# TC37X register map
File version: 1.0.0
CPU: CM4 r0p1, little endian, MPU, FPU, VTOR, 3 interrupt priority bits
Registers are 16-bit, read-write, reset 0x0 unless marked. A register's access mark holds for its fields unless they carry their own. Offsets are from the block's base; [hi:lo] are bit positions; {n}, {i} and the like mark numbered series; 'fields as' and 'values as' point back to an identical list.

## DMA — ce_sadma
Base 0xF0010000
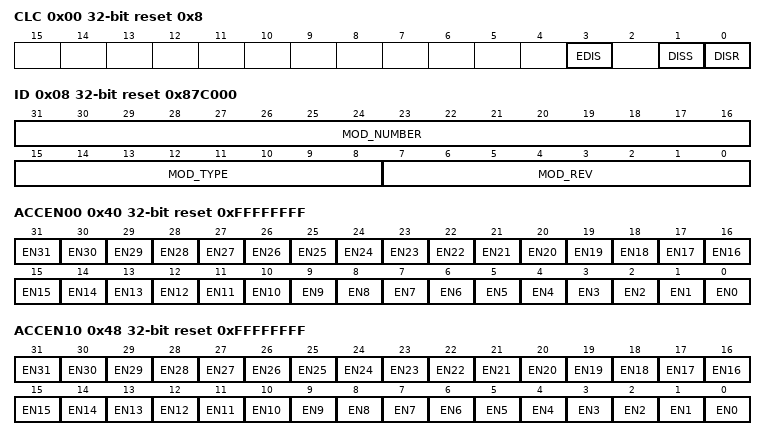
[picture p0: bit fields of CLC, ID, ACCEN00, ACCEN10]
0x00 CLC 32-bit reset 0x8 — DMA Clock Control Register
  [3] EDIS — Sleep Mode Enable Control - EDIS
  [1] DISS ro — Module Disable Status Bit - DISS
  [0] DISR — Module Disable Request Bit - DISR
0x08 ID 32-bit ro reset 0x87C000 (reset mask 0xFFFFFF00) — DMA Identification Register
  [31:16] MOD_NUMBER — Module Number Value - MOD_NUMBER
  [15:8] MOD_TYPE — Module Type - MOD_TYPE
  [7:0] MOD_REV — Module Revision Number - MOD_REV
0x40 ACCEN00 32-bit reset 0xFFFFFFFF — RP 0 Access Enable Register 0
  [n] EN{n} (n=0..31) — Access Enable for Master TAG ID q - ENq
0x44 ACCEN01 32-bit ro — RP 0 Access Enable Register 1
0x48 ACCEN10 32-bit reset 0xFFFFFFFF — RP 1 Access Enable Register 0
  [n] EN{n} (n=0..31) — Access Enable for Master TAG ID q - ENq
0x4C ACCEN11 32-bit ro — RP 1 Access Enable Register 1
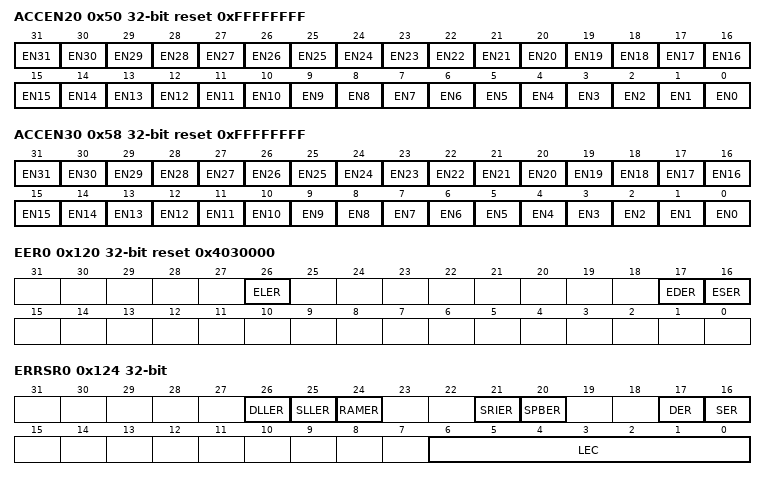
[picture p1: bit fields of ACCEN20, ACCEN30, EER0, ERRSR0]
0x50 ACCEN20 32-bit reset 0xFFFFFFFF — RP 2 Access Enable Register 0
  [n] EN{n} (n=0..31) — Access Enable for Master TAG ID q - ENq
0x54 ACCEN21 32-bit ro — RP 2 Access Enable Register 1
0x58 ACCEN30 32-bit reset 0xFFFFFFFF — RP 3 Access Enable Register 0
  [n] EN{n} (n=0..31) — Access Enable for Master TAG ID q - ENq
0x5C ACCEN31 32-bit ro — RP 3 Access Enable Register 1
0x120 EER0 32-bit reset 0x4030000 — ME 0 Enable Error Register
  [26] ELER — Enable ME DMA Linked List Error - ELER
  [17] EDER — Enable ME Destination Error - EDER
  [16] ESER — Enable ME Source Error - ESER
0x124 ERRSR0 32-bit ro — ME 0 Error Status Register
  [26] DLLER — ME DMA Linked List Error - DLLER
  [25] SLLER — ME Safe Linked List Error - SLLER
  [24] RAMER — ME RAM Error - RAMER
  [21] SRIER — ME SRI Bus Error - SRIER
  [20] SPBER — ME SPB Bus Error - SPBER
  [17] DER — ME Destination Error - DER
  [16] SER — ME Source Error - SER
  [6:0] LEC — ME Last Error Channel - LEC
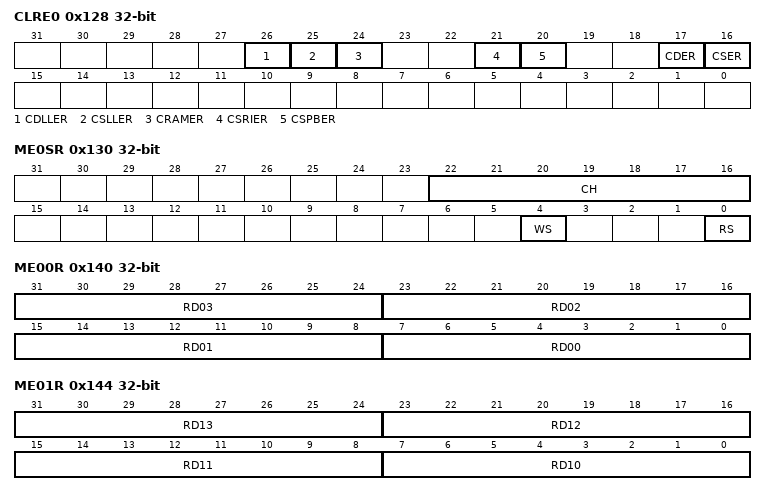
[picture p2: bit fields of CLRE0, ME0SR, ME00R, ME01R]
0x128 CLRE0 32-bit — ME 0 Clear Error Register
  [26] CDLLER wo — Clear DLL Error - CDLLER
  [25] CSLLER wo — Clear SLL Error - CSLLER
  [24] CRAMER wo — Clear RAM Error - CRAMER
  [21] CSRIER wo — Clear SRI Error - CSRIER
  [20] CSPBER wo — Clear SPB Error - CSPBER
  [17] CDER wo — Clear ME Destination Error - CDER
  [16] CSER wo — Clear ME Source Error - CSER
0x130 ME0SR 32-bit ro — ME 0 Status Register
  [22:16] CH — ME Active Channel - CH
  [4] WS — ME Write Status - WS
  [0] RS — ME Read Status - RS
0x140 ME00R 32-bit ro — ME 0 Read Register 0
  [8n+7:8n] RD{n:02} (n=0..3) — DMA Read Move Data Byte - RD{n:02}
0x144 ME01R 32-bit ro — ME 0 Read Register 1
  [8n-73:8n-80] RD{n} (n=10..13) — DMA Read Move Data Byte - RD{n}
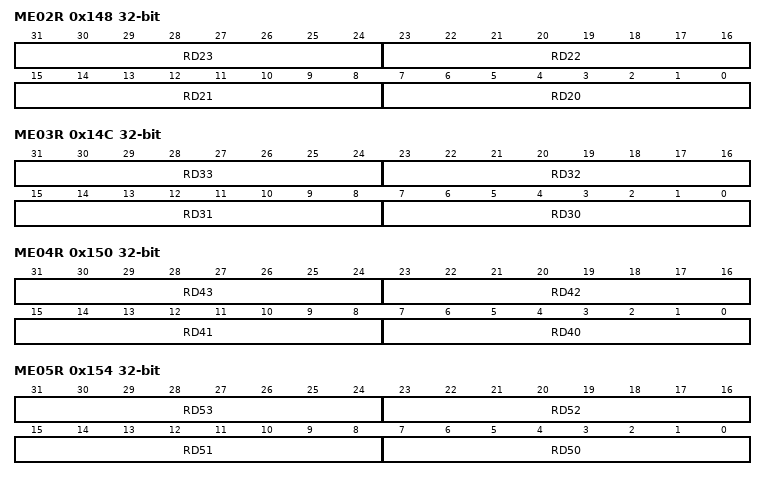
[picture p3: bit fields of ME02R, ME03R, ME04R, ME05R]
0x148 ME02R 32-bit ro — ME 0 Read Register 2
  [8n-153:8n-160] RD{n} (n=20..23) — DMA Read Move Data Byte - RD{n}
0x14C ME03R 32-bit ro — ME 0 Read Register 3
  [8n-233:8n-240] RD{n} (n=30..33) — DMA Read Move Data Byte - RD{n}
0x150 ME04R 32-bit ro — ME 0 Read Register 4
  [8n-313:8n-320] RD{n} (n=40..43) — DMA Read Move Data Byte - RD{n}
0x154 ME05R 32-bit ro — ME 0 Read Register 5
  [8n-393:8n-400] RD{n} (n=50..53) — DMA Read Move Data Byte - RD{n}
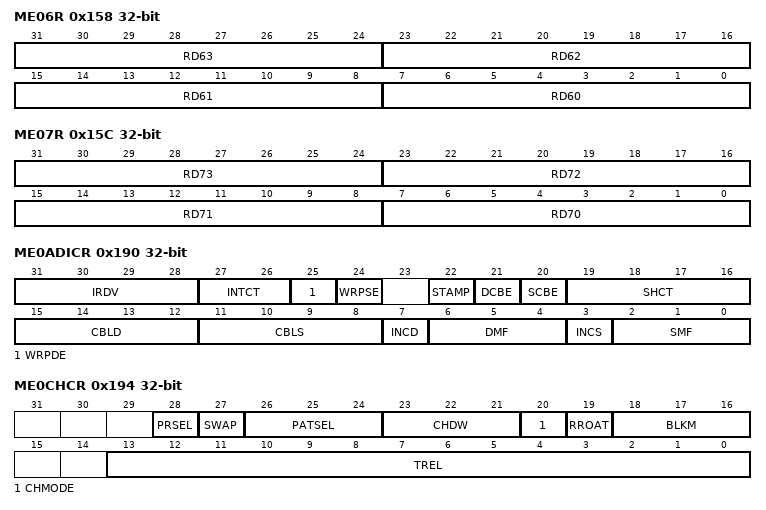
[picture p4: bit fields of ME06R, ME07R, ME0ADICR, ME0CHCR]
0x158 ME06R 32-bit ro — ME 0 Read Register 6
  [8n-473:8n-480] RD{n} (n=60..63) — DMA Read Move Data Byte - RD{n}
0x15C ME07R 32-bit ro — ME 0 Read Register 7
  [8n-553:8n-560] RD{n} (n=70..73) — DMA Read Move Data Byte - RD{n}
0x180 ME0RDCRC 32-bit ro — ME 0 Channel Read Data CRC Register
  [31:0] RDCRC — Read Data CRC - RDCRC
0x184 ME0SDCRC 32-bit ro — ME 0 Channel Source and Destination Address CRC Register
  [31:0] SDCRC — Source and Destination Address CRC - SDCRC
0x188 ME0SADR 32-bit ro — ME 0 Channel Source Address Register
  [31:0] SADR — Source Address - SADR
0x18C ME0DADR 32-bit ro — ME 0 Channel Destination Address Register
  [31:0] DADR — Destination Address - DADR
0x190 ME0ADICR 32-bit ro — ME 0 Channel Address and Interrupt Control Register
  [31:28] IRDV — Interrupt Raise Detect Value - IRDV
  [27:26] INTCT — Interrupt Control - INTCT
  [25] WRPDE — Wrap Destination Enable - WRPDE
  [24] WRPSE — Wrap Source Enable - WRPSE
  [22] STAMP — Time Stamp - STAMP
  [21] DCBE — Destination Circular Buffer Enable - DCBE
  [20] SCBE — Source Circular Buffer Enable - SCBE
  [19:16] SHCT — Shadow Control - SHCT
  [15:12] CBLD — Circular Buffer Length Destination - CBLD
  [11:8] CBLS — Circular Buffer Length Source - CBLS
  [7] INCD — Increment of Destination Address - INCD
  [6:4] DMF — Destination Address Modification Factor - DMF
  [3] INCS — Increment of Source Address - INCS
  [2:0] SMF — Source Address Modification Factor - SMF
0x194 ME0CHCR 32-bit ro — ME 0 Channel Control Register
  [28] PRSEL — Peripheral Request Select - PRSEL
  [27] SWAP — Swap Data CRC byte order - SWAP
  [26:24] PATSEL — Pattern Select - PATSEL
  [23:21] CHDW — Channel Data Width - CHDW
  [20] CHMODE — Channel Operation Mode - CHMODE
  [19] RROAT — Reset Request Only After Transaction - RROAT
  [18:16] BLKM — Block Mode - BLKM
  [13:0] TREL — Transfer Reload Value - TREL
0x198 ME0SHADR 32-bit ro — ME 0 Channel Shadow Address Register
  [31:0] SHADR — Shadowed Address - SHADR
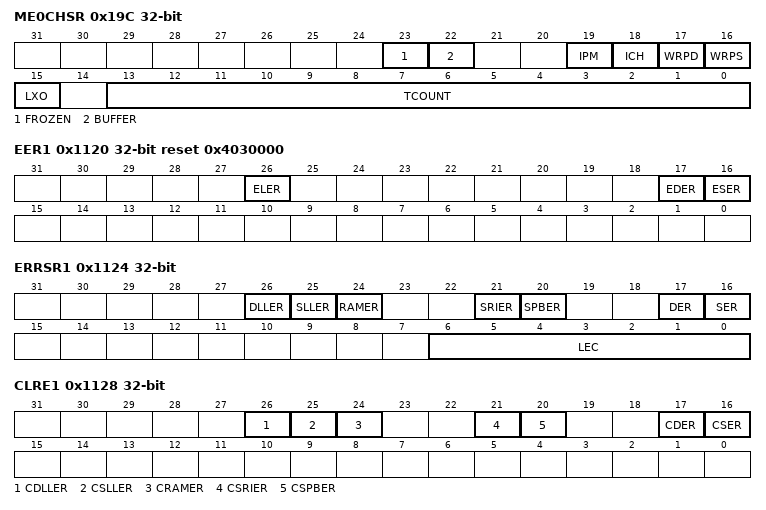
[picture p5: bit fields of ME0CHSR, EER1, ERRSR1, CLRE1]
0x19C ME0CHSR 32-bit ro — ME 0 Channel Status Register
  [23] FROZEN — DMA Double Buffering Frozen Buffer - FROZEN
  [22] BUFFER — DMA Double Buffering Active Buffer - BUFFER
  [19] IPM — Pattern Detection from Channel - IPM
  [18] ICH — Interrupt from Channel - ICH
  [17] WRPD — Wrap Destination Buffer - WRPD
  [16] WRPS — Wrap Source Buffer - WRPS
  [15] LXO — Old Value of Pattern Detection - LXO
  [13:0] TCOUNT — Transfer Count Status - TCOUNT
0x1120 EER1 32-bit reset 0x4030000 — ME 1 Enable Error Register
  fields as EER0
0x1124 ERRSR1 32-bit ro — ME 1 Error Status Register
  fields as ERRSR0
0x1128 CLRE1 32-bit — ME 1 Clear Error Register
  fields as CLRE0
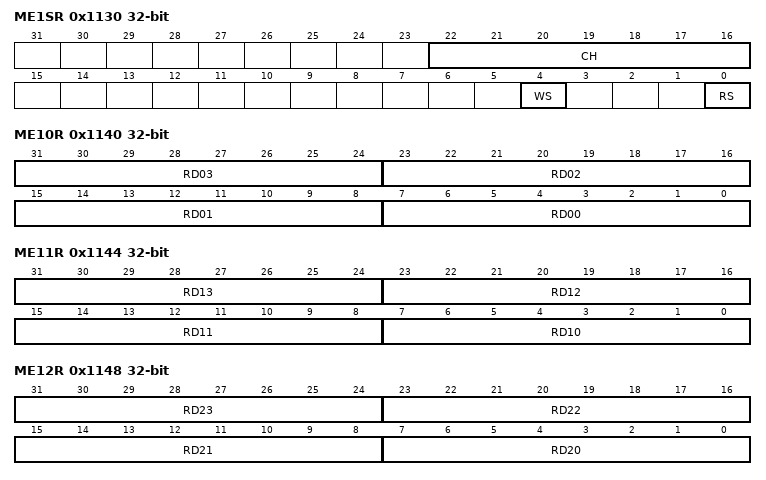
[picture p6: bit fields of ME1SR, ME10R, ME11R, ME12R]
0x1130 ME1SR 32-bit ro — ME 1 Status Register
  fields as ME0SR
0x1140 ME10R 32-bit ro — ME 1 Read Register 0
  [8n+7:8n] RD{n:02} (n=0..3) — DMA Read Move Data Byte - RD{n:02}
0x1144 ME11R 32-bit ro — ME 1 Read Register 1
  [8n-73:8n-80] RD{n} (n=10..13) — DMA Read Move Data Byte - RD{n}
0x1148 ME12R 32-bit ro — ME 1 Read Register 2
  [8n-153:8n-160] RD{n} (n=20..23) — DMA Read Move Data Byte - RD{n}
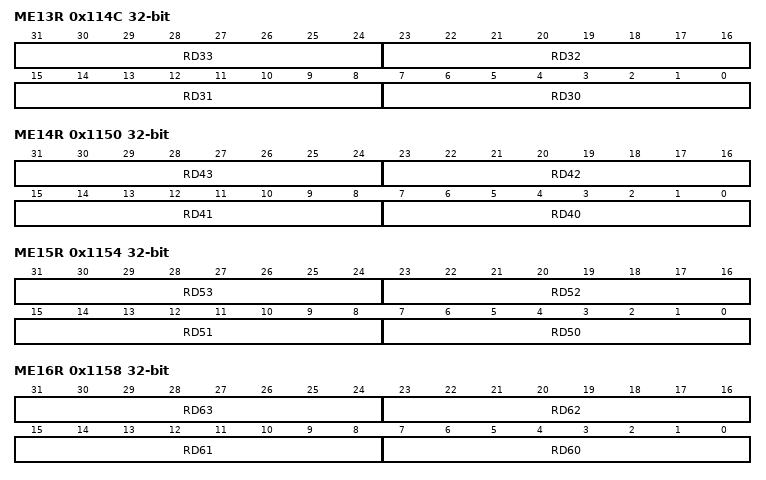
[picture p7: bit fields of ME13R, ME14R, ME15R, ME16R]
0x114C ME13R 32-bit ro — ME 1 Read Register 3
  [8n-233:8n-240] RD{n} (n=30..33) — DMA Read Move Data Byte - RD{n}
0x1150 ME14R 32-bit ro — ME 1 Read Register 4
  [8n-313:8n-320] RD{n} (n=40..43) — DMA Read Move Data Byte - RD{n}
0x1154 ME15R 32-bit ro — ME 1 Read Register 5
  [8n-393:8n-400] RD{n} (n=50..53) — DMA Read Move Data Byte - RD{n}
0x1158 ME16R 32-bit ro — ME 1 Read Register 6
  [8n-473:8n-480] RD{n} (n=60..63) — DMA Read Move Data Byte - RD{n}
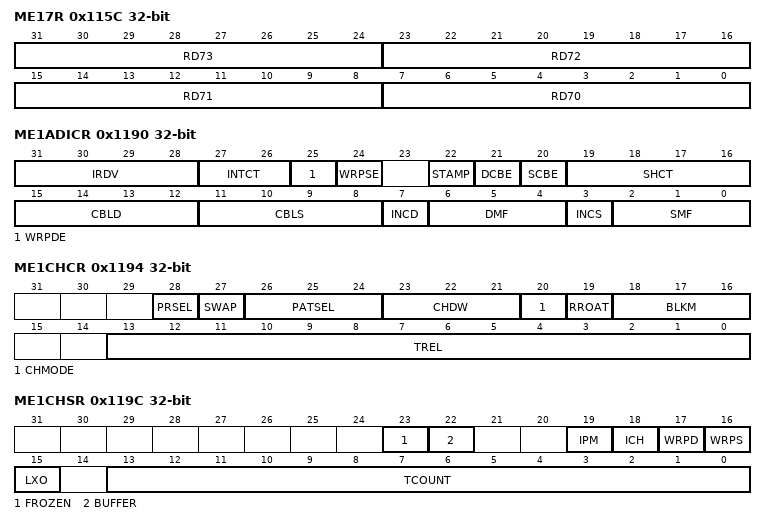
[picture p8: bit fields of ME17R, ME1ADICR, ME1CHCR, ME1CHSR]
0x115C ME17R 32-bit ro — ME 1 Read Register 7
  [8n-553:8n-560] RD{n} (n=70..73) — DMA Read Move Data Byte - RD{n}
0x1180 ME1RDCRC 32-bit ro — ME 1 Channel Read Data CRC Register
  [31:0] RDCRC — Read Data CRC - RDCRC
0x1184 ME1SDCRC 32-bit ro — ME 1 Channel Source and Destination Address CRC Register
  [31:0] SDCRC — Source and Destination Address CRC - SDCRC
0x1188 ME1SADR 32-bit ro — ME 1 Channel Source Address Register
  [31:0] SADR — Source Address - SADR
0x118C ME1DADR 32-bit ro — ME 1 Channel Destination Address Register
  [31:0] DADR — Destination Address - DADR
0x1190 ME1ADICR 32-bit ro — ME 1 Channel Address and Interrupt Control Register
  fields as ME0ADICR
0x1194 ME1CHCR 32-bit ro — ME 1 Channel Control Register
  fields as ME0CHCR
0x1198 ME1SHADR 32-bit ro — ME 1 Channel Shadow Address Register
  [31:0] SHADR — Shadowed Address - SHADR
0x119C ME1CHSR 32-bit ro — ME 1 Channel Status Register
  fields as ME0CHSR
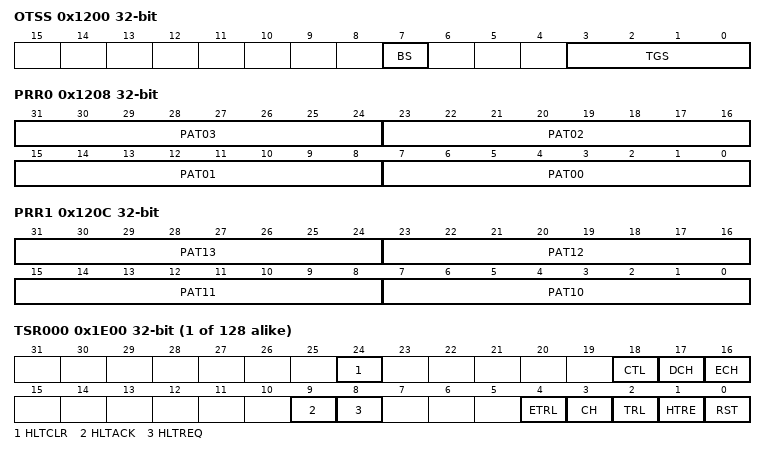
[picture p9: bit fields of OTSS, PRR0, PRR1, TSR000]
0x1200 OTSS 32-bit — DMA OCDS Trigger Set Select
  [7] BS — OTGB0 or OTGB1 Bus Select - BS
  [3:0] TGS — Trigger Set for OTGB0 or OTGB1 - TGS
0x1208 PRR0 32-bit — DMA Pattern Read Register 0
  [8n+7:8n] PAT{n:02} (n=0..3) — Pattern Data Byte - PAT{n:02}
0x120C PRR1 32-bit — DMA Pattern Read Register 1
  [8n-73:8n-80] PAT{n} (n=10..13) — Pattern Data Byte - PAT{n}
0x1210 TIME 32-bit ro — DMA Time Register
  [31:0] COUNT — Timestamp Count - COUNT
{0x1300+4i} MODE{i} 32-bit reset 0x1 (i=0..3) — RP {i} Mode Register
  [0] MODE — Resource Partition Supervisor Mode - MODE
{0x1320+4i} ERRINTR{i} 32-bit (i=0..3) — RP {i} Error Interrupt Set Register
  [0] SIT wo — Set Error Interrupt Service Request - SIT
{0x1800+4i} HRR{i:03} 32-bit (i=0..127) — DMA Channel {i:03} Resource Partition Register
  [1:0] HRP — DMA Channel Resource Partition - HRP
{0x1A00+4i} SUSENR{i:03} 32-bit (i=0..127) — DMA Channel {i:03} Suspend Enable Register
  [0] SUSEN — Channel Suspend Enable for DMA Channel - SUSEN
{0x1C00+4i} SUSACR{i:03} 32-bit ro (i=0..127) — DMA Channel {i:03} Suspend Acknowledge Register
  [0] SUSAC — DMA Channel Suspend State or Frozen State Active for DMA Channel - SUSAC
{0x1E00+4i} TSR{i:03} 32-bit (i=0..127) — DMA Channel {i:03} Transaction State Register
  [24] HLTCLR wo — Clear DMA Channel Halt Request and Acknowledge - HLTCLR
  [18] CTL wo — Clear DMA Channel Transaction/Transfer Request Lost - CTL
  [17] DCH wo — Disable DMA Channel Hardware Transaction Request - DCH
  [16] ECH wo — Enable DMA Channel Hardware Transaction Request - ECH
  [9] HLTACK ro — DMA Channel Halt Acknowledge - HLTACK
  [8] HLTREQ — DMA Channel Halt Request - HLTREQ
  [4] ETRL — Enable DMA Channel Transaction/Transfer Request Lost Interrupt - ETRL
  [3] CH ro — DMA Channel Transaction Request State - CH
  [2] TRL ro — DMA Channel Transaction/Transfer Request Lost - TRL
  [1] HTRE ro — DMA Channel Hardware Request Enable - HTRE
  [0] RST — DMA Channel Reset - RST
{0x2000+0x20*i} RDCRCR{i:03} 32-bit (i=0..127) — DMARAM Channel {i:03} Read Data CRC Register
  [31:0] RDCRC — Read Data CRC - RDCRC
{0x2004+0x20*i} SDCRCR{i:03} 32-bit (i=0..127) — DMARAM Channel {i:03} Source and Destination Address CRC Register
  [31:0] SDCRC — Source and Destination Address CRC - SDCRC
{0x2008+0x20*i} SADR{i:03} 32-bit (i=0..127) — DMARAM Channel {i:03} Source Address Register
  [31:0] SADR — Source Address - SADR
{0x200C+0x20*i} DADR{i:03} 32-bit (i=0..127) — DMARAM Channel {i:03} Destination Address Register
  [31:0] DADR — Destination Address - DADR
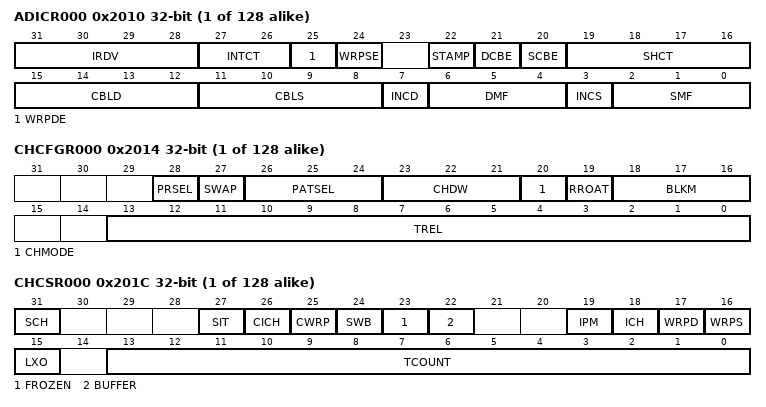
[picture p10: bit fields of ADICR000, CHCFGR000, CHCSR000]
{0x2010+0x20*i} ADICR{i:03} 32-bit (i=0..127) — DMARAM Channel {i:03} Address and Interrupt Control Register
  fields as ME0ADICR
{0x2014+0x20*i} CHCFGR{i:03} 32-bit (i=0..127) — DMARAM Channel {i:03} Configuration Register
  [28] PRSEL — Peripheral Request Select - PRSEL
  [27] SWAP — Swap Data CRC Byte Order - SWAP
  [26:24] PATSEL — Pattern Select - PATSEL
  [23:21] CHDW — Channel Data Width - CHDW
  [20] CHMODE — Channel Operation Mode - CHMODE
  [19] RROAT — Reset Request Only After Transaction - RROAT
  [18:16] BLKM — Block Mode - BLKM
  [13:0] TREL — Transfer Reload Value - TREL
{0x2018+0x20*i} SHADR{i:03} 32-bit (i=0..127) — DMARAM Channel {i:03} Shadow Address Register
  [31:0] SHADR — Shadowed Address - SHADR
{0x201C+0x20*i} CHCSR{i:03} 32-bit (i=0..127) — DMARAM Channel {i:03} Control and Status Register
  [31] SCH wo — Set Transaction Request - SCH
  [27] SIT wo — Set Interrupt Trigger for DMA Channel - SIT
  [26] CICH wo — Clear Interrupt for DMA Channel - CICH
  [25] CWRP wo — Clear Wrap Buffer Interrupt - CWRP
  [24] SWB wo — DMA Double Buffering Switch Buffer - SWB
  [23] FROZEN — DMA Double Buffering Frozen Buffer - FROZEN
  [22] BUFFER ro — DMA Double Buffering Active Buffer - BUFFER
  [19] IPM ro — Pattern Detection from Channel - IPM
  [18] ICH ro — Interrupt from Channel - ICH
  [17] WRPD ro — Wrap Destination Buffer - WRPD
  [16] WRPS ro — Wrap Source Buffer - WRPS
  [15] LXO ro — Old Value of Pattern Detection - LXO
  [13:0] TCOUNT ro — Transfer Count - TCOUNT
